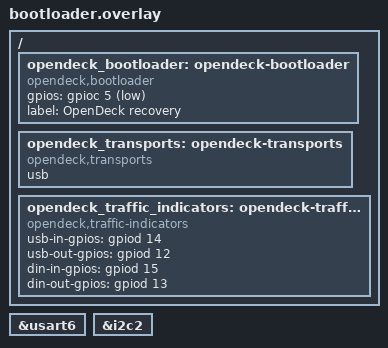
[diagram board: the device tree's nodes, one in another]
opendeck_uart_din_midi: &usart6 {};

opendeck_uart_touchscreen: &usart6 {};

opendeck_i2c_display: &i2c2 {};

/ {
    opendeck_bootloader: opendeck-bootloader {
        compatible = "opendeck,bootloader";
        gpios = <&gpioc 5 (GPIO_PULL_UP | GPIO_ACTIVE_LOW)>;
        label = "OpenDeck recovery";
    };

    opendeck_transports: opendeck-transports {
        compatible = "opendeck,transports";
        usb;
    };

    opendeck_traffic_indicators: opendeck-traffic-indicators {
        compatible = "opendeck,traffic-indicators";
        usb-in-gpios = <&gpiod 14 GPIO_ACTIVE_HIGH>;
        usb-out-gpios = <&gpiod 12 GPIO_ACTIVE_HIGH>;
        din-in-gpios = <&gpiod 15 GPIO_ACTIVE_HIGH>;
        din-out-gpios = <&gpiod 13 GPIO_ACTIVE_HIGH>;
    };
};
